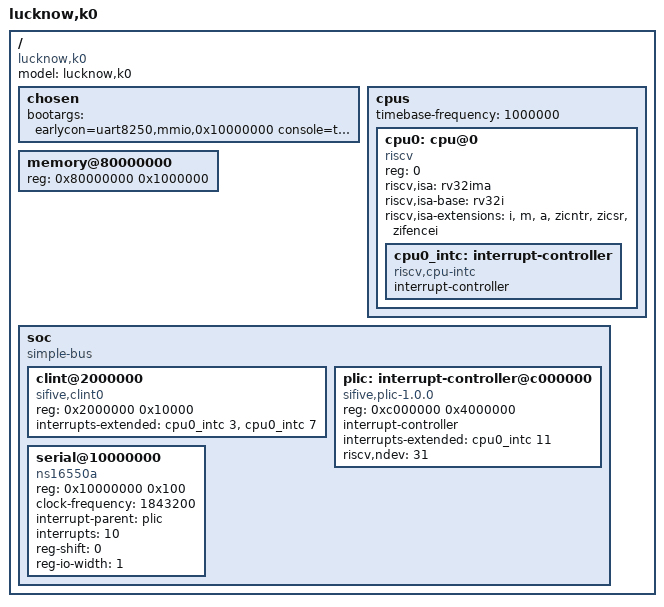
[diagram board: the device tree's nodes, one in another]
/dts-v1/;

/ {
	#address-cells = <1>;
	#size-cells = <1>;
	compatible = "lucknow,k0";
	model = "lucknow,k0";

	chosen {
		bootargs = "earlycon=uart8250,mmio,0x10000000 console=ttyS0 rdinit=/init";
	};

	cpus {
		#address-cells = <1>;
		#size-cells = <0>;
		timebase-frequency = <1000000>; // mtime counts clocks, the real value depends on the clock

		cpu0: cpu@0 {
			device_type = "cpu";
			compatible = "riscv";
			reg = <0>;
			riscv,isa = "rv32ima";
			riscv,isa-base = "rv32i";
			riscv,isa-extensions = "i", "m", "a", "zicntr", "zicsr", "zifencei";
			status = "okay";

			cpu0_intc: interrupt-controller {
				#interrupt-cells = <1>;
				compatible = "riscv,cpu-intc";
				interrupt-controller;
			};
		};
	};

	memory@80000000 {
		device_type = "memory";
		reg = <0x80000000 0x1000000>; // 16 MiB, RAM_WORDS = 4194304
	};

	soc {
		#address-cells = <1>;
		#size-cells = <1>;
		compatible = "simple-bus";
		ranges;

		clint@2000000 {
			compatible = "sifive,clint0", "riscv,clint0";
			reg = <0x2000000 0x10000>;
			interrupts-extended = <&cpu0_intc 3>, <&cpu0_intc 7>;
		};

		plic: interrupt-controller@c000000 {
			compatible = "sifive,plic-1.0.0", "riscv,plic0";
			reg = <0xc000000 0x4000000>;
			#interrupt-cells = <1>;
			interrupt-controller;
			interrupts-extended = <&cpu0_intc 11>;
			riscv,ndev = <31>;
		};

		serial@10000000 {
			compatible = "ns16550a";
			reg = <0x10000000 0x100>;
			clock-frequency = <1843200>;
			interrupt-parent = <&plic>;
			interrupts = <10>;
			reg-shift = <0>;
			reg-io-width = <1>;
		};
	};
};
